# NUC100BN_v1 register map
File version: 1.0
Registers are 32-bit, read-write, reset 0x0 unless marked. A register's access mark holds for its fields unless they carry their own. Offsets are from the block's base; [hi:lo] are bit positions; {n}, {i} and the like mark numbered series.

## GCR — GCR Register Map
Base 0x50000000
0x00 PDID ro reset 0x140018 — Part Device Identification Number Register
  [31:0] PDID — Part Device Identification Number. This register reflects device part number code. S/W can read this register to identify which device is used.
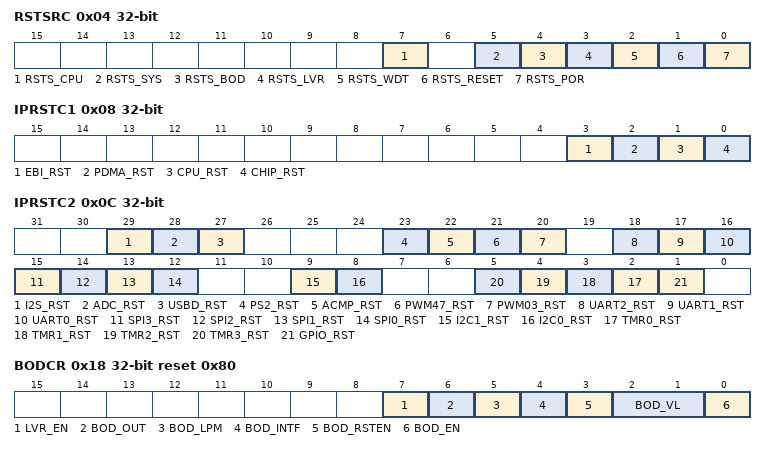
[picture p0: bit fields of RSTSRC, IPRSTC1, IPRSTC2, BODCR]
0x04 RSTSRC (reset mask 0xFFFFFF00) — System Reset Source Register
  [7] RSTS_CPU — The RSTS_CPU flag is set by hardware if software writes CPU_RST (IPRSTC1[1]) 1 to reset Cortex-M0 CPU kernel and Flash memory controller (FMC). Write 1 to clear this bit to 0.
    0=No reset from CPU; 1=Cortex-M0 CPU kernel and FMC are reset by software setting CPU_RST to 1
  [5] RSTS_SYS — The RSTS_SYS flag is set by the "reset signal" from the Cortex_M0 kernel to indicate the previous reset source. Write 1 to clear this bit to 0.
    0=No reset from Cortex_M0; 1=Cortex_M0 had issued the reset signal to reset the system by writing 1 to bit SYSRESETREQ(AIRCR[2], Application Interrupt and Reset Control Register, address = 0xE000ED0C) in system control registers of Cortex_M0 kernel
  [4] RSTS_BOD — The RSTS_BOD flag is set by the "reset signal" from the Brown-out-Detector to indicate the previous reset source. Write 1 to clear this bit to 0.
    0=No reset from BOD; 1=BOD had issued the reset signal to reset the system
  [3] RSTS_LVR — The RSTS_LVR flag is set by the "reset signal" from the Low-Voltage-Reset controller to indicate the previous reset source. Write 1 to clear this bit to 0.
    0=No reset from LVR; 1=LVR controller had issued the reset signal to reset the system
  [2] RSTS_WDT — The RSTS_WDT flag is set by the "reset signal" from the watchdog timer to indicate the previous reset source. Write 1 to clear this bit to 0.
    0=No reset from watchdog timer; 1=Watchdog timer had issued the reset signal to reset the system
  [1] RSTS_RESET — The RSTS_RESET flag is set by the "reset signal" from the /RESET pin to indicate the previous reset source. Write 1 to clear this bit to 0.
    0=No reset from /RESET pin; 1=Pin /RESET had issued the reset signal to reset the system
  [0] RSTS_POR — The RSTS_POR flag is set by the "reset signal" from the Power-On Reset (POR) controller or bit CHIP_RST (IPRSTC1[0]) to indicate the previous reset source. Write 1 to clear this bit to 0.
    0=No reset from POR or CHIP_RST; 1=Power-On Reset (POR) or CHIP_RST had issued the reset signal to reset the system
0x08 IPRSTC1 — IP Reset Control Register 1
  [3] EBI_RST — EBI Controller Reset (NuMicro( NUC100/NUC120 Low Density 64 pin Package Only) (Write-protection Bit in NuMicro( NUC100/NUC120 Low Density 64-pin Package). Set this bit to 1 will generate a reset signal to the EBI. User needs to set this bit to 0 to release from the reset state. This bit is the protected bit, It means programming this bit needs to write "59h", "16h", "88h" to address 0x5000_0100 to disable register protection. Refer to the register REGWRPROT at address GCR_BA+0x100.
    0=EBI controller normal operation; 1=EBI controller reset
  [2] PDMA_RST — PDMA Controller Reset (Write-protection Bit in NuMicro( NUC100/NUC120 Low Density). Setting this bit to 1 will generate a reset signal to the PDMA. User needs to set this bit to 0 to release from reset state. This bit is the protected bit, which means programming this bit needs to write "59h", "16h", "88h" to address 0x5000_0100 to disable register protection. Refer to the register REGWRPROT at address GCR_BA+0x100.
    0=PDMA controller normal operation; 1=PDMA controller reset
  [1] CPU_RST — CPU Kernel one-shot reset (Write-protection Bit). Setting this bit will only reset the CPU kernel and Flash Memory Controller(FMC), and this bit will automatically return 0 after two clock cycles. This bit is the protected bit, It means programming this bit needs to write "59h", "16h", "88h" to address 0x5000_0100 to disable register protection. Refer to the register REGWRPROT at address GCR_BA+0x100.
    0=CPU normal operation; 1=CPU one-shot reset
  [0] CHIP_RST — CHIP One-shot Reset (Write-Protection Bit). Setting this bit will reset the whole chip, including CPU kernel and all peripherals, and this bit will automatically return to 0 after the 2 clock cycles. The CHIP_RST is same as the POR reset, all the chip controllers is reset and the chip setting from flash are also reload. About the difference between CHIP_RST and SYSRESETREQ, please refer to section 5.2.2. This bit is the protected bit. It means programming this bit needs to write "59h", "16h", "88h" to address 0x5000_0100 to disable register protection. Refer to the register REGWRPROT at address GCR_BA+0x100
    0=CHIP normal operation; 1=CHIP one-shot reset
0x0C IPRSTC2 — IP Reset Control Register 2
  [29] I2S_RST — I2S Controller Reset
    0=I2S controller normal operation; 1=I2S controller reset
  [28] ADC_RST — ADC Controller Reset
    0=ADC controller normal operation; 1=ADC controller reset
  [27] USBD_RST — USB Device Controller Reset
    0=USB device controller normal operation; 1=USB device controller reset
  [23] PS2_RST — PS/2 Controller Reset
    0=PS/2 controller normal operation; 1=PS/2 controller reset
  [22] ACMP_RST — Analog Comparator Controller Reset
    0=Analog Comparator controller normal operation; 1=Analog Comparator controller reset
  [21] PWM47_RST — PWM47 controller Reset (NuMicro( NUC100/NUC120 Medium Density Only)
    0=PWM47 controller normal operation; 1=PWM47 controller reset
  [20] PWM03_RST — PWM03 controller Reset
    0=PWM03 controller normal operation; 1=PWM03 controller reset
  [18] UART2_RST — UART2 controller Reset (NuMicro( NUC100/NUC120 Medium Density Only)
    0=UART2 controller normal operation; 1=UART2 controller reset
  [17] UART1_RST — UART1 controller Reset
    0=UART1 controller normal operation; 1=UART1 controller reset
  [16] UART0_RST — UART0 controller Reset
    0=UART0 controller normal operation; 1=UART0 controller reset
  [15] SPI3_RST — SPI3 controller Reset (NuMicro( NUC100/NUC120 Medium Density Only)
    0=SPI3 controller normal operation; 1=SPI3 controller reset
  [14] SPI2_RST — SPI2 controller Reset (NuMicro( NUC100/NUC120 Medium Density Only)
    0=SPI2 controller normal operation; 1=SPI2 controller reset
  [13] SPI1_RST — SPI1 controller Reset
    0=SPI1 controller normal operation; 1=SPI1 controller reset
  [12] SPI0_RST — SPI0 controller Reset
    0=SPI0 controller normal operation; 1=SPI0 controller reset
  [9] I2C1_RST — I2C1 controller Reset
    0=I2C1 controller normal operation; 1=I2C1 controller reset
  [8] I2C0_RST — I2C0 controller Reset
    0=I2C0 controller normal operation; 1=I2C0 controller reset
  [n+2] TMR{n}_RST (n=0..3) — Timer{n} controller Reset
    0=Timer{n} controller normal operation; 1=Timer{n} controller reset
  [1] GPIO_RST — GPIO controller Reset
    0=GPIO controller normal operation; 1=GPIO controller reset
0x10 CPR — Chip Performance Register
  [0] HPE — High Performance Enable (Write-Protection Bit). This bit is used to control chip operation performance. When this bit set, internal RAM and GPIO access is working with zero wait state, and Flash controller will predict next address more efficiently. The high performance is enabled without limiting by chip operation frequency.
    0=Chip operation at normal mode; 1=Chip operation at high performance mode
0x18 BODCR reset 0x80 (reset mask 0xFFFFFFF0) — Brown-out Detector Control Register
  [7] LVR_EN — Low Voltage Reset Enable (Write-Protection Bit). The LVR function reset the chip when the input power voltage is lower than LVR circuit setting. LVR function is enabled in default. This bit is the protected bit. It means programming this needs to write "59h", "16h", "88h" to address 0x5000_0100 to disable register protection. Refer to the register REGWRPROT at address GCR_BA+0x100
    0=Low Voltage Reset function Disabled; 1=Low Voltage Reset function Enabled - After enabling the bit, the LVR function will be active with 100uS delay for LVR output stable. (Default)
  [6] BOD_OUT — Brown-out Detector output status
    0=Brown-out Detector output status is 0. It means the detected voltage is higher than BOD_VL setting or BOD_EN is 0; 1=Brown-out Detector output status is 1. It means the detected voltage is lower than BOD_VL setting. If the BOD_EN is 0, BOD function disabled , this bit always responds 0
  [5] BOD_LPM — Brown-out Detector Low power Mode (Write-Protection Bit). The BOD consumes about 100 uA in Normal mode, and the low power mode can reduce the current to about 1/10 but slow the BOD response. This bit is the protected bit, which means programming this needs to write "59h", "16h", "88h" to address 0x5000_0100 to disable register protection. Refer to the register REGWRPROT at address GCR_BA+0x100.
    0=BOD operated in Normal mode (default); 1=BOD low power mode Enabled
  [4] BOD_INTF — Brown-out Detector Interrupt Flag. Write 1 to clear this bit to 0.
    0=Brown-out Detector does not detect any voltage draft at VDD down through or up through the voltage of BOD_VL setting; 1=When Brown-out Detector detects the VDD is dropped down through the voltage of BOD_VL setting or the VDD is raised up through the voltage of BOD_VL setting, this bit is set to 1 and the Brown-out interrupt is requested if Brown-out interrupt is enabled
  [3] BOD_RSTEN — Brown-out Reset Enable (Write-Protection Bit). While the BOD function is enabled (BOD_EN high) and BOD interrupt function is enabled (BOD_RSTEN low), BOD will assert an interrupt if BOD_OUT is high. BOD interrupt will keep till to the BOD_EN set to 0. BOD interrupt can be blocked by disabling the NVIC BOD interrupt or disabling BOD function (set BOD_EN low). The default value is set by flash controller user configuration register config0 bit[20]. This bit is the protected bit. It means programming this needs to write "59h", "16h", "88h" to address 0x5000_0100 to disable register protection. Refer to the register REGWRPROT at address GCR_BA+0x100.
    0=Brown-out "INTERRUPT" function Enabled; 1=Brown-out "RESET" function Enabled
  [2:1] BOD_VL — Brown-out Detector Threshold Voltage Selection (Write-Protection Bit)
  [0] BOD_EN — Brown-out Detector Enable (write-protection bit). The default value is set by flash controller user configuration register config0 bit[23]. This bit is the protected bit, which means programming this needs to write "59h", "16h", "88h" to address 0x5000_0100 to disable register protection. Refer to the register REGWRPROT at address GCR_BA+0x100.
    0=Brown-out Detector function Disabled; 1=Brown-out Detector function Enabled
0x1C TEMPCR — Temperature Sensor Control Register
  [0] VTEMP_EN — Temperature Sensor Enable. This bit is used to enable/disable temperature sensor function. After this bit is set to 1, the value of temperature can be obtained from ADC conversion result by ADC channel selecting channel 7 and alternative multiplexer channel selecting temperature sensor. Please refer to the ADC function chapter for detailed ADC conversion function description.
    0=Temperature sensor function Disabled (default); 1=Temperature sensor function Enabled
0x24 PORCR (reset mask 0xFFFFFF00) — Power-On-reset Controller Register
  [15:0] POR_DIS_CODE — Power-On-Reset Enable Control (Write-protection Bits). When powered on, the POR circuit generates a reset signal to reset the whole chip function, but noise on the power may cause the POR active again. User can disable internal POR circuit to avoid unpredictable noise to cause chip reset by writing 0x5AA5 to this field. The POR function will be active again when this field is set to another value or chip is reset by other reset source, including: /RESET, Watchdog, LVR reset, BOD reset, ICE reset command and the software-chip reset function. This bit is the protected bit, which means programming this needs to write "59h", "16h", "88h" to address 0x5000_0100 to disable register protection. Refer to the register REGWRPROT at address GCR_BA+0x100.
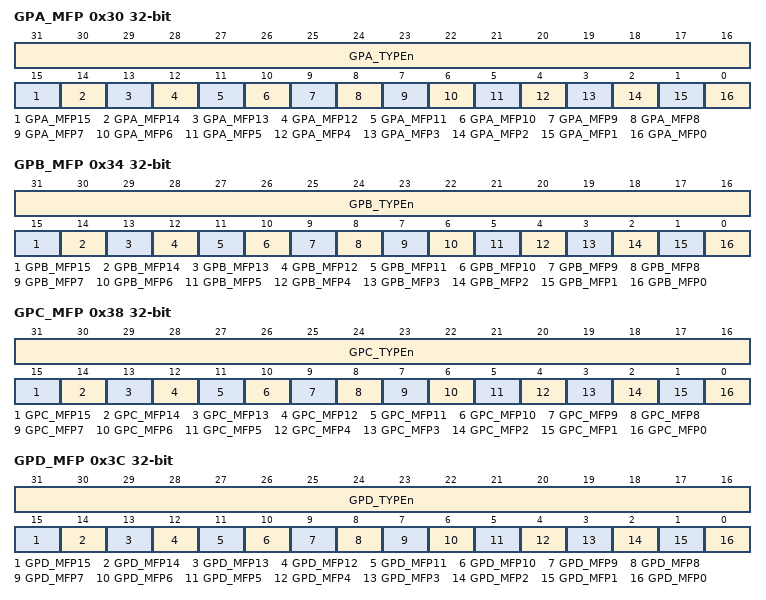
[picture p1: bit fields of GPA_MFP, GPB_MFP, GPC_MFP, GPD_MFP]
0x30 GPA_MFP — GPIOA Multiple Function and Input Type Control Register
  [31:16] GPA_TYPEn
    0=GPIOA[15:0] I/O input Schmitt Trigger function Disabled; 1=GPIOA[15:0] I/O input Schmitt Trigger function Enabled
  [15] GPA_MFP15 — PA.15 Pin Function Selection
  [14] GPA_MFP14 — PA.14 Pin Function Selection
  [13] GPA_MFP13 — PA.13 Pin Function Selection
  [12] GPA_MFP12 — PA.12 Pin Function Selection
  [11] GPA_MFP11 — PA.11 Pin Function Selection
  [10] GPA_MFP10 — PA.10 Pin Function Selection
  [9] GPA_MFP9 — PA.9 Pin Function Selection
    0=GPIOA[9] selected to the pin PA.9; 1=I2C0 SCL function selected to the pin PA.9
  [8] GPA_MFP8 — PA.8 Pin Function Selection
    0=GPIOA[8] selected to the pin PA.8; 1=I2C0 SDA function selected to the pin PA.8
  [7] GPA_MFP7 — PA.7 Pin Function Selection
  [6] GPA_MFP6 — PA.6 Pin Function Selection
  [5] GPA_MFP5 — PA.5 Pin Function Selection
  [4] GPA_MFP4 — PA.4 Pin Function Selection
  [3] GPA_MFP3 — PA.3 Pin Function Selection
  [2] GPA_MFP2 — PA.2 Pin Function Selection
  [1] GPA_MFP1 — PA.1 Pin Function Selection
  [0] GPA_MFP0 — PA.0 Pin Function Selection
    0=GPIOA[0] selected to the pin PA.0; 1=ADC0 (Analog-to-Digital converter channel 0) function selected to the pin PA.0
0x34 GPB_MFP — GPIOB Multiple Function and Input Type Control Register
  [31:16] GPB_TYPEn
    0=GPIOB[15:0] I/O input Schmitt Trigger function Disabled; 1=GPIOB[15:0] I/O input Schmitt Trigger function Enabled
  [15] GPB_MFP15 — PB.15 Pin Function Selection
    0=GPIOB[15] selected to the pin PB.15; 1=External Interrupt INT1 function selected to the pin PB.15
  [14] GPB_MFP14 — PB.14 Pin Function Selection
  [13] GPB_MFP13 — PB.13 Pin Function Selection
  [12] GPB_MFP12 — PB.12 Pin Function Selection
  [11] GPB_MFP11 — PB.11 Pin Function Selection
  [10] GPB_MFP10 — PB.10 Pin Function Selection
  [9] GPB_MFP9 — PB.9 Pin Function Selection
  [8] GPB_MFP8 — PB.8 Pin Function Selection
    0=GPIOB[8] selected to the pin PB.8; 1=TM0 (Timer/Counter external trigger clock input) function selected to the pin PB.8
  [7] GPB_MFP7 — PB.7 Pin Function Selection
  [6] GPB_MFP6 — PB.6 Pin Function Selection
  [5] GPB_MFP5 — PB. 5 Pin Function Selection
    0=GPIOB[5] is selected to the pin PB.5; 1=UART1 TXD function is selected to the pin PB.5
  [4] GPB_MFP4 — PB.4 Pin Function Selection
    0=GPIOB[4] selected to the pin PB.4; 1=UART1 RXD function selected to the pin PB.4
  [3] GPB_MFP3 — PB.3 Pin Function Selection
  [2] GPB_MFP2 — PB.2 Pin Function Selection
  [1] GPB_MFP1 — PB.1 Pin Function Selection
    0=GPIOB[1] selected to the pin PB.1; 1=UART0 TXD function selected to the pin PB.1
  [0] GPB_MFP0 — PB.0 Pin Function Selection
    0=GPIOB[0] selected to the pin PB.0; 1=UART0 RXD function selected to the pin PB.0
0x38 GPC_MFP — GPIOC Multiple Function and Input Type Control Register
  [31:16] GPC_TYPEn
    0=GPIOC[15:0] I/O input Schmitt Trigger function Disabled; 1=GPIOC[15:0] I/O input Schmitt Trigger function Enabled
  [15] GPC_MFP15 — PC.15 Pin Function Selection
  [14] GPC_MFP14 — PC.14 Pin Function Selection
  [13] GPC_MFP13 — PC.13 Pin Function Selection
    0=GPIOC[13] selected to the pin PC.13; 1=SPI1 MOSI1 (master output, slave input pin-1) function selected to the pin PC.13
  [12] GPC_MFP12 — PC.12 Pin Function Selection
    0=GPIOC[12] selected to the pin PC.12; 1=SPI1 MISO1 (master input, slave output pin-1) function selected to the pin PC.12
  [11] GPC_MFP11 — PC.11 Pin Function Selection
    0=GPIOC[11] selected to the pin PC.11; 1=SPI1 MOSI0 (master output, slave input pin-0) function selected to the pin PC.11
  [10] GPC_MFP10 — PC.10 Pin Function Selection
    0=GPIOC[10] is selected to the pin PC.10; 1=SPI1 MISO0 (master input, slave output pin-0) function selected to the pin PC.10
  [9] GPC_MFP9 — PC.9 Pin Function Selection
    0=GPIOC[9] selected to the pin PC.9; 1=SPI1 SPICLK function selected to the pin PC.9
  [8] GPC_MFP8 — PC.8 Pin Function Selection
  [7] GPC_MFP7 — PC.7 Pin Function Selection
  [6] GPC_MFP6 — PC.6 Pin Function Selection
  [5] GPC_MFP5 — PC.5 Pin Function Selection
    0=GPIOC[5] is selected to the pin PC.5; 1=SPI0 MOSI1 (master output, slave input pin-1) function is selected to the pin PC.5
  [4] GPC_MFP4 — PC.4 Pin Function Selection
    0=GPIOC[4] is selected to the pin PC.4; 1=SPI0 MISO1 (master input, slave output pin-1) function is selected to the pin PC.4
  [3] GPC_MFP3 — PC.3 Pin Function Selection
  [2] GPC_MFP2 — PC.2 Pin Function Selection
  [1] GPC_MFP1 — PC.1 Pin Function Selection
  [0] GPC_MFP0 — PC.0 Pin Function Selection
0x3C GPD_MFP — GPIOD Multiple Function and Input Type Control Register
  [31:16] GPD_TYPEn
    0=GPIOD[15:0] I/O input Schmitt Trigger function Disabled; 1=GPIOD[15:0] I/O input Schmitt Trigger function Enabled
  [15] GPD_MFP15 — PD.15 Pin Function Selection (NuMicro( NUC100/NUC120 Medium Density Only)
    0=GPIOD[15] selected to the pin PD.15; 1=UART2 TXD function selected to the pin PD.15
  [14] GPD_MFP14 — PD.14 Pin Function Selection (NuMicro( NUC100/NUC120 Medium Density Only)
    0=GPIOD[14] selected to the pin PD.14; 1=UART2 RXD function is selected to the pin PD.14
  [13] GPD_MFP13 — PD.13 Pin Function Selection (NuMicro( NUC100/NUC120 Medium Density Only)
    0=GPIOD[13] selected to the pin PD.13; 1=SPI3 MOSI1 (master output, slave input pin-1) function selected to the pin PD.13
  [12] GPD_MFP12 — PD.12 Pin Function Selection (NuMicro( NUC100/NUC120 Medium Density Only)
    0=GPIOD[12] selected to the pin PD.12; 1=SPI3 MISO1 (master input, slave output pin-1) function selected to the pin PD.12
  [11] GPD_MFP11 — PD.11 Pin Function Selection (NuMicro( NUC100/NUC120 Medium Density Only)
    0=GPIOD[11] selected to the pin PD.11; 1=SPI3 MOSI0 (master output, slave input pin-0) function selected to the pin PD.11
  [10] GPD_MFP10 — PD.10 Pin Function Selection (NuMicro( NUC100/NUC120 Medium Density Only)
    0=GPIOD[10] selected to the pin PD.10; 1=SPI3 MISO0 (master input, slave output pin-0) function selected to the pin PD.10
  [9] GPD_MFP9 — PD.9 Pin Function Selection (NuMicro( NUC100/NUC120 Medium Density Only)
    0=GPIOD[9] selected to the pin PD.9; 1=SPI3 SPICLK function selected to the pin PD.9
  [8] GPD_MFP8 — PD.8 Pin Function Selection (NuMicro( NUC100/NUC120 Medium Density Only)
    0=GPIOD[8] selected to the pin PD8; 1=SPI3 SS30 function selected to the pin PD8
  [7] GPD_MFP7 — Reserved
  [6] GPD_MFP6 — Reserved
  [5] GPD_MFP5 — PD.5 Pin Function Selection (NuMicro( NUC100/NUC120 Medium Density Only)
    0=GPIOD[5] is selected to the pin PD.5; 1=SPI2 MOSI1 (master output, slave input pin-1) function selected to the pin PD.5
  [4] GPD_MFP4 — PD.4 Pin Function Selection (NuMicro( NUC100/NUC120 Medium Density Only)
    0=GPIOD[4]is selected to the pin PD.4; 1=SPI2 MISO1 (master input, slave output pin-1) function selected to the pin PD.4
  [3] GPD_MFP3 — PD.3 Pin Function Selection. For NuMicro( NUC100/NUC120 Medium Density: For NuMicro( NUC100/NUC120 Low Density: Reserved
    0=GPIOD[3] selected to the pin PD.3; 1=SPI2 MOSI0 (master output, slave input pin-0) function selected to the pin PD.3
  [2] GPD_MFP2 — PD.2 Pin Function Selection. For NuMicro( NUC100/NUC120 Medium Density: For NuMicro( NUC100/NUC120 Low Density: Reserved
    0=GPIOD[2] selected to the pin PD.2; 1=SPI2 MISO0 (master input, slave output pin-0) function selected to the pin PD.2
  [1] GPD_MFP1 — PD.1 Pin Function Selection. For NuMicro( NUC100/NUC120 Medium Density: For NuMicro( NUC100/NUC120 Low Density: Reserved
    0=GPIOD[1] selected to the pin PD.1; 1=SPI2 SPICLK function selected to the pin PD.1
  [0] GPD_MFP0 — PD.0 Pin Function Selection (NuMicro( NUC100/NUC120 Medium Density Only)
    0=GPIOD[0] selected to the pin PD.0; 1=SPI2 SS20 function selected to the pin PD.0
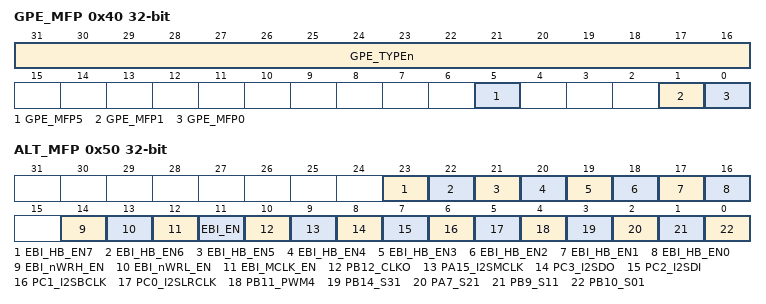
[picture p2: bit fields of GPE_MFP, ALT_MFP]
0x40 GPE_MFP — GPIOE Multiple Function and Input Type Control Register
  [31:16] GPE_TYPEn — Note: In this field, NuMicro( NUC100/NUC120 Low Density only has GPE_TYPE5 bit.
    0=GPIOE[15:0] I/O input Schmitt Trigger function Disabled; 1=GPIOE[15:0] I/O input Schmitt Trigger function Enabled
  [5] GPE_MFP5 — PE.5 Pin Function Selection (NuMicro( NUC100/NUC120 Medium Density Only)
    0=GPIOE[5] selected to the pin PE.5; 1=PWM5 function selected to the pin PE.5
  [1] GPE_MFP1 — PE.1 Pin Function Selection (NuMicro( NUC100/NUC120 Medium Density Only)
    0=GPIOE[1] selected to the pin PE.1; 1=PWM7 function selected to the pin PE.1
  [0] GPE_MFP0 — PE.0 Pin Function Selection (NuMicro( NUC100/NUC120 Medium Density Only)
    0=GPIOE[0] selected to the pin PE.0; 1=PWM6 function selected to the pin PE.0
0x50 ALT_MFP — Alternative Multiple Function Pin Control Register
  [23] EBI_HB_EN7 — EBI_HB_EN is used to switch GPIO function to EBI address/data bus high byte (AD[15:8]), EBI_HB_EN, EBI_EN and the corresponding GPx_MFP[y] determine the Px.y function.
  [22] EBI_HB_EN6 — Bits EBI_HB_EN[6], EBI_EN and GPA_MFP[13] determine the PA.13 function.
  [21] EBI_HB_EN5 — Bits EBI_HB_EN[5], EBI_EN and GPA_MFP[12] determine the PA.12 function.
  [20] EBI_HB_EN4 — Bits EBI_HB_EN[4], EBI_EN and GPA_MFP[1] determine the PA.1 function.
  [19] EBI_HB_EN3 — Bits EBI_HB_EN[3], EBI_EN and GPA_MFP[2] determine the PA.2 function.
  [18] EBI_HB_EN2 — Bits EBI_HB_EN[2], EBI_EN and GPA_MFP[3] determine the PA.3 function.
  [17] EBI_HB_EN1 — Bits EBI_HB_EN[1], EBI_EN and GPA_MFP[4] determine the PA.4 function.
  [16] EBI_HB_EN0 — Bits EBI_HB_EN[0], EBI_EN and GPA_MFP[5] determine the PA.5 function.
  [14] EBI_nWRH_EN — Bits EBI_nWRH_EN, EBI_EN and GPB_MFP[3] determine the PB.3 function.
  [13] EBI_nWRL_EN — Bits EBI_nWRL_EN, EBI_EN and GPB_MFP[2] determine the PB.2 function.
  [12] EBI_MCLK_EN — Bits EBI_MCLK_EN, EBI_EN and GPC_MFP[8] determine the PC.8 function.
  [11] EBI_EN — EBI_EN is used to switch GPIO function to EBI function (AD[15:0], ALE, RE, WE, CS, MCLK), which needs additional registers EBI_EN[7:0] and EBI_MCLK_EN for some GPIO to switch to EBI function(AD[15:8], MCLK).
  [10] PB12_CLKO — Bits PB12_CLKO, GPB_MFP[12] and EBI_EN (ALT_MFP[11]) determine the PB.12 function.
  [9] PA15_I2SMCLK — Bits PA15_I2SMCLK and GPA_MFP[15] determine the PA.15 function.
  [8] PC3_I2SDO — Bits PC3_I2SDO and GPC_MFP[3] determine the PC.3 function.
  [7] PC2_I2SDI — Bits PC2_I2SDI and GPC_MFP[2] determine the PC.2 function.
  [6] PC1_I2SBCLK — Bits PC1_I2SBCLK and GPC_MFP[1] determine the PC.1 function.
  [5] PC0_I2SLRCLK — Bits PC0_I2SLRCLK and GPC_MFP[0] determine the PC.0 function.
  [4] PB11_PWM4 — Bits PB11_PWM4 and GPB_MFP[11] determine the PB.11 function.
  [3] PB14_S31 — Bits PB14_S31 and GPB_MFP[14] determine the PB.14 function.
  [2] PA7_S21 — Bits PA7_S21, GPA_MFP[7] and EBI_EN (ALT_MFP[11]).determine the PA.7 function.
  [1] PB9_S11 — Bits PB9_S11 and GPB_MFP[9] determine the PB.9 function.
  [0] PB10_S01 — Bits PB10_S01 and GPB_MFP[10] determine the PB.10 function.
0x100 REGWRPROT — Register Write Protect Register
  [7:0] REGWRPROT — Register Write-Protection Code (Write Only). Some registers have write-protection function. Writing these registers have to disable the protected function by writing the sequence value "59h", "16h", "88h" to this field. After this sequence is completed, the REGPROTDIS bit will be set to 1 and write-protection registers can be normal write. Register Write-Protection Disable index (Read only). The Protected registers are: IPRSTC1: address 0x5000_0008. CPR: address 0x5000_0010 (Low Density only). BODCR: address 0x5000_0018. PORCR: address 0x5000_0024. PWRCON: address 0x5000_0200 (bit[6] is not protected for power wake-up interrupt clear). APBCLK bit[0]: address 0x5000_0208 (bit[0] is watchdog clock enable). CLKSEL0: address 0x5000_0210 (for HCLK and CPU STCLK clock source select). CLKSEL1 bit[1:0]: address 0x5000_0214 (for watchdog clock source select). ISPCON: address 0x5000_C000 (Flash ISP Control register). ISPTRG: address 0x5000_C010 (ISP Trigger Control register). WTCR: address 0x4000_4000. FATCON: address 0x5000_C018
    0=Write-protection Enabled for writing protected registers. Any write to the protected register is ignored; 1=Write-protection Disabled for writing protected registers
